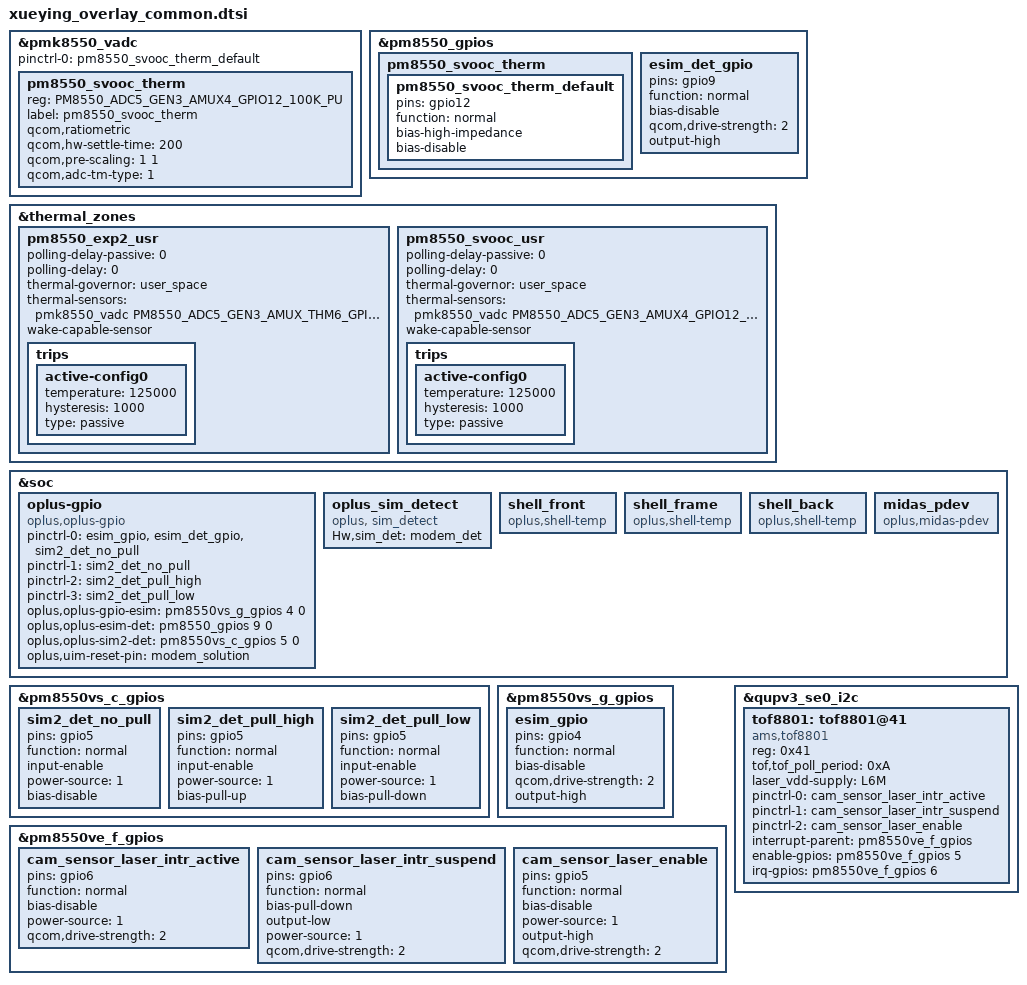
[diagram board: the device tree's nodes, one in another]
// Add the thermistors of explorer and svooc
&pmk8550_vadc {
	pinctrl-0 = <&pm8550_svooc_therm_default>;
	pinctrl-names = "default";

	pm8550_svooc_therm {
		reg = <PM8550_ADC5_GEN3_AMUX4_GPIO12_100K_PU>;
		label = "pm8550_svooc_therm";
		qcom,ratiometric;
		qcom,hw-settle-time = <200>;
		qcom,pre-scaling = <1 1>;
		qcom,adc-tm-type = <1>;
	};
};

&pm8550_gpios {
	pm8550_svooc_therm {
		pm8550_svooc_therm_default: pm8550_svooc_therm_default {
			pins = "gpio12";
			function = "normal"; //normal
			bias-high-impedance;
			bias-disable;
		};
	};
};
/*
&pmk8550_vadc {
	pm8550_exp2_therm {
		reg = <PM8550_ADC5_GEN3_AMUX_THM6_GPIO2_100K_PU>;
		label = "pm8550_exp2_therm";
		qcom,ratiometric;
		qcom,hw-settle-time = <200>;
		qcom,pre-scaling = <1 1>;
		qcom,adc-tm-type = <1>;
	};
};
*/
&thermal_zones {
	pm8550_exp2_usr {
		polling-delay-passive = <0>;
		polling-delay = <0>;
		thermal-governor = "user_space";
		thermal-sensors = <&pmk8550_vadc PM8550_ADC5_GEN3_AMUX_THM6_GPIO2_100K_PU>;
		wake-capable-sensor;
		trips {
			active-config0 {
				temperature = <125000>;
				hysteresis = <1000>;
				type = "passive";
			};
		};
	};

	pm8550_svooc_usr {
		polling-delay-passive = <0>;
		polling-delay = <0>;
		thermal-governor = "user_space";
		thermal-sensors = <&pmk8550_vadc PM8550_ADC5_GEN3_AMUX4_GPIO12_100K_PU>;
		wake-capable-sensor;
		trips {
			active-config0 {
				temperature = <125000>;
				hysteresis = <1000>;
				type = "passive";
			};
		};
	};
};

&soc {
	//#ifdef OPLUS_FEATRUE_ESIM
	oplus-gpio {
		compatible = "oplus,oplus-gpio";
		pinctrl-names = "default", "sim2_det_no_pull", "sim2_det_pull_high", "sim2_det_pull_low";
		pinctrl-0 = <&esim_gpio &esim_det_gpio &sim2_det_no_pull>;
		pinctrl-1 = <&sim2_det_no_pull>;
		pinctrl-2 = <&sim2_det_pull_high>;
		pinctrl-3 = <&sim2_det_pull_low>;
		oplus,oplus-gpio-esim = <&pm8550vs_g_gpios 4 0>;
		oplus,oplus-esim-det = <&pm8550_gpios 9 0>;
		oplus,oplus-sim2-det = <&pm8550vs_c_gpios 5 0>;
		oplus,uim-reset-pin = "modem_solution";
	};
	//#endif /* OPLUS_FEATRUE_ESIM */
	oplus_sim_detect {
		compatible = "oplus, sim_detect";
		Hw,sim_det = "modem_det";
	};
	//#ifdef OPLUS_FEATURE_THERMAL_HORAE
	shell_front {
		compatible = "oplus,shell-temp";
	};

	shell_frame {
		compatible = "oplus,shell-temp";
	};

	shell_back {
		compatible = "oplus,shell-temp";
	};
	//#endif /* OPLUS_FEATURE_THERMAL_HORAE */

	midas_pdev {
		compatible = "oplus,midas-pdev";
	};
};

&pm8550vs_c_gpios {
	sim2_det_no_pull: sim2_det_no_pull {
			pins = "gpio5";
			function = "normal";
			input-enable;
			power-source = <1>;
			bias-disable;
	};

	sim2_det_pull_high: sim2_det_pull_high {
			pins = "gpio5";
			function = "normal";
			input-enable;
			power-source = <1>;
			bias-pull-up;
	};

	sim2_det_pull_low: sim2_det_pull_low {
			pins = "gpio5";
			function = "normal";
			input-enable;
			power-source = <1>;
			bias-pull-down;
	};
};

&pm8550vs_g_gpios {
	esim_gpio: esim_gpio  {
			pins = "gpio4";
			function = "normal";
			bias-disable; /* NO pull */
			qcom,drive-strength = <2>; /* 2 MA */
			output-high;
	};
};

&pm8550_gpios {
	esim_det_gpio: esim_det_gpio {
			pins = "gpio9";
			function = "normal";
			bias-disable; /* NO pull */
			qcom,drive-strength = <2>; /* 2 MA */
			output-high;
	};
};

&pm8550ve_f_gpios {

	cam_sensor_laser_intr_active: cam_sensor_laser_intr_active {
		pins = "gpio6";
		function = "normal";
		bias-disable;
		power-source = <1>; /* 1.8V */
		qcom,drive-strength = <2>;
	};

	cam_sensor_laser_intr_suspend: cam_sensor_laser_intr_suspend {
		pins = "gpio6";
		function = "normal";
		bias-pull-down; /* PULL DOWN */
		output-low;
		power-source = <1>; /* 1.8V */
		qcom,drive-strength = <2>;
	};

	cam_sensor_laser_enable: cam_sensor_laser_enable {
		pins = "gpio5";
		function = "normal";
		bias-disable;
		power-source = <1>;
		output-high;
		qcom,drive-strength = <2>;
	};

};

&qupv3_se0_i2c {
    tof8801: tof8801@41 {
        compatible = "ams,tof8801";
        reg = <0x41>;
        tof,tof_poll_period = <0xA>; /*poll period (100 usec)*/
        laser_vdd-supply = <&L6M>;
        pinctrl-names = "laser_default", "laser_suspend", "default";
        pinctrl-0 = <&cam_sensor_laser_intr_active>;
        pinctrl-1 = <&cam_sensor_laser_intr_suspend>;
        pinctrl-2 =  <&cam_sensor_laser_enable>;
        interrupt-parent = <&pm8550ve_f_gpios>;
        enable-gpios = <&pm8550ve_f_gpios 5 0>;
        irq-gpios = <&pm8550ve_f_gpios 6 0>;
        status = "ok";
    };
};

